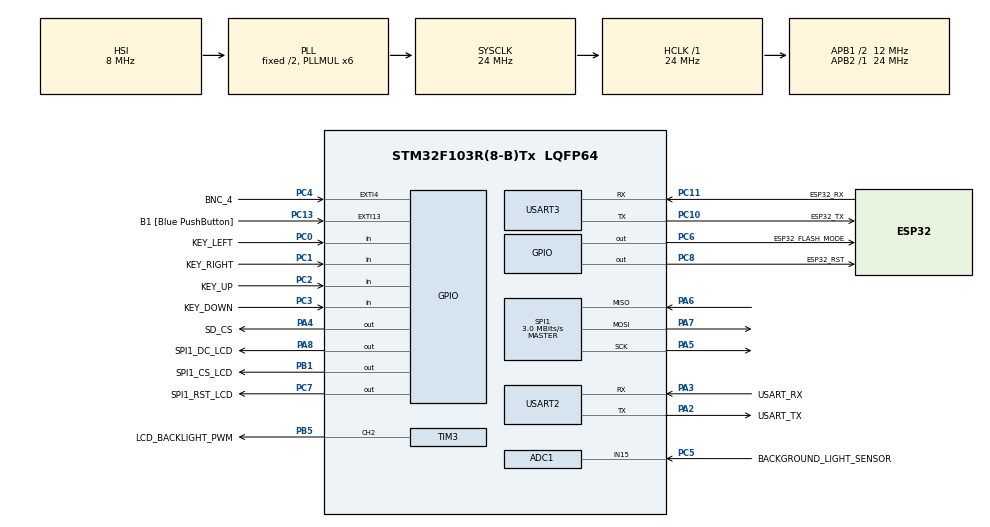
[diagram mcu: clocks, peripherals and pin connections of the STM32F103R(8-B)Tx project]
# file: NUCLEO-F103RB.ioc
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ADC1.Channel-3\#ChannelRegularConversion=ADC_CHANNEL_15
ADC1.ContinuousConvMode=ENABLE
ADC1.EnableRegularConversion=ENABLE
ADC1.NbrOfConversionFlag=1
ADC1.Rank-3\#ChannelRegularConversion=1
ADC1.SamplingTime-3\#ChannelRegularConversion=ADC_SAMPLETIME_1CYCLE_5
ADC1.master=1
Dma.ADC1.0.Direction=DMA_PERIPH_TO_MEMORY
Dma.ADC1.0.Instance=DMA1_Channel1
Dma.ADC1.0.MemDataAlignment=DMA_MDATAALIGN_WORD
Dma.ADC1.0.MemInc=DMA_MINC_ENABLE
Dma.ADC1.0.Mode=DMA_CIRCULAR
Dma.ADC1.0.PeriphDataAlignment=DMA_PDATAALIGN_WORD
Dma.ADC1.0.PeriphInc=DMA_PINC_DISABLE
Dma.ADC1.0.Priority=DMA_PRIORITY_MEDIUM
Dma.Request0=ADC1
Mcu.Family=STM32F1
Mcu.Name=STM32F103R(8-B)Tx
Mcu.Package=LQFP64
NVIC.DMA1_Channel1_IRQn=true\:0\:0\:false\:true\:true\:2\:false\:true\:true
NVIC.EXTI15_10_IRQn=true\:0\:0\:false\:true\:true\:3\:true\:true\:true
NVIC.EXTI4_IRQn=true\:0\:0\:false\:true\:true\:1\:true\:true\:true
NVIC.PriorityGroup=NVIC_PRIORITYGROUP_4
PA13.GPIO_Label=TMS
PA13.Mode=Serial_Wire
PA13.Signal=SYS_JTMS-SWDIO
PA14.GPIO_Label=TCK
PA14.Mode=Serial_Wire
PA14.Signal=SYS_JTCK-SWCLK
PA2.GPIO_Label=USART_TX
PA2.GPIO_Mode=GPIO_MODE_AF_PP
PA2.GPIO_PuPd=GPIO_NOPULL
PA2.GPIO_Speed=GPIO_SPEED_FREQ_LOW
PA2.Mode=Asynchronous
PA2.Signal=USART2_TX
PA3.GPIO_Label=USART_RX
PA3.GPIO_Mode=GPIO_MODE_AF_PP
PA3.GPIO_PuPd=GPIO_NOPULL
PA3.GPIO_Speed=GPIO_SPEED_FREQ_LOW
PA3.Mode=Asynchronous
PA3.Signal=USART2_RX
PA4.GPIO_Label=SD_CS
PA4.GPIO_PuPd=GPIO_PULLUP
PA4.Signal=GPIO_Output
PA5.Mode=Full_Duplex_Master
PA5.Signal=SPI1_SCK
PA6.GPIO_PuPd=GPIO_PULLUP
PA6.Mode=Full_Duplex_Master
PA6.Signal=SPI1_MISO
PA7.Mode=Full_Duplex_Master
PA7.Signal=SPI1_MOSI
PA8.GPIO_Label=SPI1_DC_LCD
PA8.GPIO_PuPd=GPIO_PULLUP
PA8.Signal=GPIO_Output
PB1.GPIO_Label=SPI1_CS_LCD
PB1.GPIO_PuPd=GPIO_PULLUP
PB1.Signal=GPIO_Output
PB3.GPIO_Label=SWO
PB3.Signal=SYS_JTDO-TRACESWO
PB5.GPIO_Label=LCD_BACKLIGHT_PWM
PB5.GPIO_Speed=GPIO_SPEED_FREQ_HIGH
PB5.Signal=S_TIM3_CH2
PC0.GPIO_Label=KEY_LEFT
PC0.GPIO_PuPd=GPIO_PULLUP
PC0.Signal=GPIO_Input
PC1.GPIO_Label=KEY_RIGHT
PC1.GPIO_PuPd=GPIO_PULLUP
PC1.Signal=GPIO_Input
PC10.GPIO_Label=ESP32_TX
PC10.Mode=Asynchronous
PC10.Signal=USART3_TX
PC11.GPIO_Label=ESP32_RX
PC11.Mode=Asynchronous
PC11.Signal=USART3_RX
PC12.Signal=USART3_CK
PC13-TAMPER-RTC.GPIO_Label=B1 [Blue PushButton]
PC13-TAMPER-RTC.GPIO_PuPd=GPIO_NOPULL
PC13-TAMPER-RTC.Signal=GPXTI13
PC14-OSC32_IN.Mode=LSE-External-Oscillator
PC14-OSC32_IN.Signal=RCC_OSC32_IN
PC15-OSC32_OUT.Mode=LSE-External-Oscillator
PC15-OSC32_OUT.Signal=RCC_OSC32_OUT
PC2.GPIO_Label=KEY_UP
PC2.GPIO_PuPd=GPIO_PULLUP
PC2.Signal=GPIO_Input
PC3.GPIO_Label=KEY_DOWN
PC3.GPIO_PuPd=GPIO_PULLUP
PC3.Signal=GPIO_Input
PC4.GPIO_Label=BNC_4
PC4.Signal=GPXTI4
PC5.GPIO_Label=BACKGROUND_LIGHT_SENSOR
PC5.Signal=ADCx_IN15
PC6.GPIO_Label=ESP32_FLASH_MODE
PC6.PinState=GPIO_PIN_SET
PC6.Signal=GPIO_Output
PC7.GPIO_Label=SPI1_RST_LCD
PC7.GPIO_PuPd=GPIO_PULLUP
PC7.PinState=GPIO_PIN_SET
PC7.Signal=GPIO_Output
PC8.GPIO_Label=ESP32_RST
PC8.PinState=GPIO_PIN_SET
PC8.Signal=GPIO_Output
PD0-OSC_IN.Mode=HSE-External-Oscillator
PD0-OSC_IN.Signal=RCC_OSC_IN
PD1-OSC_OUT.Mode=HSE-External-Oscillator
PD1-OSC_OUT.Signal=RCC_OSC_OUT
ProjectManager.HeapSize=0x200
ProjectManager.StackSize=0x400
ProjectManager.TargetToolchain=CMake
RCC.ADCPresc=RCC_ADCPCLK2_DIV8
RCC.AHBFreq_Value=24000000
RCC.APB1CLKDivider=RCC_HCLK_DIV2
RCC.APB1Freq_Value=12000000
RCC.APB1TimFreq_Value=24000000
RCC.APB2Freq_Value=24000000
RCC.APB2TimFreq_Value=24000000
RCC.HCLKFreq_Value=24000000
RCC.PLLMUL=RCC_PLL_MUL6
RCC.RTCClockSelection=RCC_RTCCLKSOURCE_LSE
RCC.SYSCLKFreq_VALUE=24000000
RCC.SYSCLKSource=RCC_SYSCLKSOURCE_PLLCLK
RCC.USBFreq_Value=24000000
SH.ADCx_IN15.0=ADC1_IN15,IN15
SH.S_TIM3_CH2.0=TIM3_CH2,PWM Generation2 CH2
SPI1.BaudRatePrescaler=SPI_BAUDRATEPRESCALER_8
SPI1.CalculateBaudRate=3.0 MBits/s
SPI1.Direction=SPI_DIRECTION_2LINES
SPI1.Mode=SPI_MODE_MASTER
SPI1.VirtualType=VM_MASTER
TIM3.Channel-PWM\ Generation2\ CH2=TIM_CHANNEL_2
TIM3.OCMode_PWM-PWM\ Generation2\ CH2=TIM_OCMODE_PWM2
TIM3.Period=100
TIM3.Prescaler=8
TIM3.Pulse-PWM\ Generation2\ CH2=30
USART2.VirtualMode=VM_ASYNC
USART3.VirtualMode=VM_ASYNC
VP_FATFS_VS_Generic.Mode=User_defined
VP_RTC_VS_RTC_Activate.Mode=RTC_Enabled
board=NUCLEO-F103RB

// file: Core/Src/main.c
/* USER CODE BEGIN Header */
/**
 ******************************************************************************
 * @file           : main.c
 * @brief          : Main program body
 ******************************************************************************
 * @attention
 *
 * Copyright (c) 2024 STMicroelectronics.
 * All rights reserved.
 *
 * This software is licensed under terms that can be found in the LICENSE file
 * in the root directory of this software component.
 * If no LICENSE file comes with this software, it is provided AS-IS.
 *
 ******************************************************************************
 */
/* USER CODE END Header */
#include "main.h"
#include "fatfs.h"

/* USER CODE BEGIN Includes */
#include "MyApplication.hpp"
/* USER CODE END Includes */

ADC_HandleTypeDef hadc1;
DMA_HandleTypeDef hdma_adc1;

RTC_HandleTypeDef hrtc;

SPI_HandleTypeDef hspi1;

TIM_HandleTypeDef htim3;

UART_HandleTypeDef huart2;
UART_HandleTypeDef huart3;

/* USER CODE BEGIN PV */

extern ADC_HandleTypeDef hadc1;
/*
// Declare a buffer to hold ADC values
#define ADC_BUFFER_SIZE 1  // Adjust size based on your needs
volatile uint32_t adcBuffer[ADC_BUFFER_SIZE];

void startADCWithDMA()
{
    // Start ADC in DMA mode
    HAL_StatusTypeDef statusFromHal = HAL_ADC_Start_DMA(&hadc1,  (uint32_t *)adcBuffer, ADC_BUFFER_SIZE);

    //return (statusFromHal == HAL_OK);
}
*/
/* USER CODE END PV */

void SystemClock_Config(void);
static void MX_GPIO_Init(void);
static void MX_DMA_Init(void);
static void MX_USART2_UART_Init(void);
static void MX_RTC_Init(void);
static void MX_SPI1_Init(void);
static void MX_ADC1_Init(void);
static void MX_USART3_UART_Init(void);
static void MX_TIM3_Init(void);
static void MX_NVIC_Init(void);

int main(void)
{

  /* MCU Configuration--------------------------------------------------------*/

  /* Reset of all peripherals, Initializes the Flash interface and the Systick. */
  HAL_Init();

  /* Configure the system clock */
  SystemClock_Config();

  /* Initialize all configured peripherals */
  MX_GPIO_Init();
  MX_DMA_Init();
  MX_USART2_UART_Init();
  MX_FATFS_Init();
  MX_RTC_Init();
  MX_SPI1_Init();
  MX_ADC1_Init();
  MX_USART3_UART_Init();
  MX_TIM3_Init();

  /* Initialize interrupts */
  MX_NVIC_Init();
  /* USER CODE BEGIN 2 */
  // startADCWithDMA();
  app_init();
  app_start(); // maybe do a bit of sleep before calling it
  /* USER CODE END 2 */

  /* Infinite loop */
  while (1)
  {

    /* USER CODE BEGIN 3 */
    app_tick();
  }
  /* USER CODE END 3 */
}

void SystemClock_Config(void)
{
  RCC_OscInitTypeDef RCC_OscInitStruct = {0};
  RCC_ClkInitTypeDef RCC_ClkInitStruct = {0};
  RCC_PeriphCLKInitTypeDef PeriphClkInit = {0};

  /** Initializes the RCC Oscillators according to the specified parameters
  * in the RCC_OscInitTypeDef structure.
  */
  RCC_OscInitStruct.OscillatorType = RCC_OSCILLATORTYPE_HSI|RCC_OSCILLATORTYPE_LSE;
  RCC_OscInitStruct.LSEState = RCC_LSE_ON;
  RCC_OscInitStruct.HSIState = RCC_HSI_ON;
  RCC_OscInitStruct.HSICalibrationValue = RCC_HSICALIBRATION_DEFAULT;
  RCC_OscInitStruct.PLL.PLLState = RCC_PLL_ON;
  RCC_OscInitStruct.PLL.PLLSource = RCC_PLLSOURCE_HSI_DIV2;
  RCC_OscInitStruct.PLL.PLLMUL = RCC_PLL_MUL6;
  if (HAL_RCC_OscConfig(&RCC_OscInitStruct) != HAL_OK)
  {
    Error_Handler();
  }

  /** Initializes the CPU, AHB and APB buses clocks
  */
  RCC_ClkInitStruct.ClockType = RCC_CLOCKTYPE_HCLK|RCC_CLOCKTYPE_SYSCLK
                              |RCC_CLOCKTYPE_PCLK1|RCC_CLOCKTYPE_PCLK2;
  RCC_ClkInitStruct.SYSCLKSource = RCC_SYSCLKSOURCE_PLLCLK;
  RCC_ClkInitStruct.AHBCLKDivider = RCC_SYSCLK_DIV1;
  RCC_ClkInitStruct.APB1CLKDivider = RCC_HCLK_DIV2;
  RCC_ClkInitStruct.APB2CLKDivider = RCC_HCLK_DIV1;

  if (HAL_RCC_ClockConfig(&RCC_ClkInitStruct, FLASH_LATENCY_0) != HAL_OK)
  {
    Error_Handler();
  }
  PeriphClkInit.PeriphClockSelection = RCC_PERIPHCLK_RTC|RCC_PERIPHCLK_ADC;
  PeriphClkInit.RTCClockSelection = RCC_RTCCLKSOURCE_LSE;
  PeriphClkInit.AdcClockSelection = RCC_ADCPCLK2_DIV8;
  if (HAL_RCCEx_PeriphCLKConfig(&PeriphClkInit) != HAL_OK)
  {
    Error_Handler();
  }
}

/**
  * @brief NVIC Configuration.
  * @retval None
  */
static void MX_NVIC_Init(void)
{
  /* EXTI4_IRQn interrupt configuration */
  HAL_NVIC_SetPriority(EXTI4_IRQn, 0, 0);
  HAL_NVIC_EnableIRQ(EXTI4_IRQn);
  /* DMA1_Channel1_IRQn interrupt configuration */
  HAL_NVIC_SetPriority(DMA1_Channel1_IRQn, 0, 0);
  HAL_NVIC_EnableIRQ(DMA1_Channel1_IRQn);
  /* EXTI15_10_IRQn interrupt configuration */
  HAL_NVIC_SetPriority(EXTI15_10_IRQn, 0, 0);
  HAL_NVIC_EnableIRQ(EXTI15_10_IRQn);
}

static void MX_ADC1_Init(void)
{

  ADC_ChannelConfTypeDef sConfig = {0};

  /** Common config
  */
  hadc1.Instance = ADC1;
  hadc1.Init.ScanConvMode = ADC_SCAN_DISABLE;
  hadc1.Init.ContinuousConvMode = ENABLE;
  hadc1.Init.DiscontinuousConvMode = DISABLE;
  hadc1.Init.ExternalTrigConv = ADC_SOFTWARE_START;
  hadc1.Init.DataAlign = ADC_DATAALIGN_RIGHT;
  hadc1.Init.NbrOfConversion = 1;
  if (HAL_ADC_Init(&hadc1) != HAL_OK)
  {
    Error_Handler();
  }

  /** Configure Regular Channel
  */
  sConfig.Channel = ADC_CHANNEL_15;
  sConfig.Rank = ADC_REGULAR_RANK_1;
  sConfig.SamplingTime = ADC_SAMPLETIME_1CYCLE_5;
  if (HAL_ADC_ConfigChannel(&hadc1, &sConfig) != HAL_OK)
  {
    Error_Handler();
  }

}

static void MX_RTC_Init(void)
{

  /** Initialize RTC Only
  */
  hrtc.Instance = RTC;
  hrtc.Init.AsynchPrediv = RTC_AUTO_1_SECOND;
  hrtc.Init.OutPut = RTC_OUTPUTSOURCE_ALARM;
  if (HAL_RTC_Init(&hrtc) != HAL_OK)
  {
    Error_Handler();
  }

}

static void MX_SPI1_Init(void)
{

  /* SPI1 parameter configuration*/
  hspi1.Instance = SPI1;
  hspi1.Init.Mode = SPI_MODE_MASTER;
  hspi1.Init.Direction = SPI_DIRECTION_2LINES;
  hspi1.Init.DataSize = SPI_DATASIZE_8BIT;
  hspi1.Init.CLKPolarity = SPI_POLARITY_LOW;
  hspi1.Init.CLKPhase = SPI_PHASE_1EDGE;
  hspi1.Init.NSS = SPI_NSS_SOFT;
  hspi1.Init.BaudRatePrescaler = SPI_BAUDRATEPRESCALER_8;
  hspi1.Init.FirstBit = SPI_FIRSTBIT_MSB;
  hspi1.Init.TIMode = SPI_TIMODE_DISABLE;
  hspi1.Init.CRCCalculation = SPI_CRCCALCULATION_DISABLE;
  hspi1.Init.CRCPolynomial = 10;
  if (HAL_SPI_Init(&hspi1) != HAL_OK)
  {
    Error_Handler();
  }

}

static void MX_TIM3_Init(void)
{

  TIM_MasterConfigTypeDef sMasterConfig = {0};
  TIM_OC_InitTypeDef sConfigOC = {0};

  htim3.Instance = TIM3;
  htim3.Init.Prescaler = 8;
  htim3.Init.CounterMode = TIM_COUNTERMODE_UP;
  htim3.Init.Period = 100;
  htim3.Init.ClockDivision = TIM_CLOCKDIVISION_DIV1;
  htim3.Init.AutoReloadPreload = TIM_AUTORELOAD_PRELOAD_DISABLE;
  if (HAL_TIM_PWM_Init(&htim3) != HAL_OK)
  {
    Error_Handler();
  }
  sMasterConfig.MasterOutputTrigger = TIM_TRGO_RESET;
  sMasterConfig.MasterSlaveMode = TIM_MASTERSLAVEMODE_DISABLE;
  if (HAL_TIMEx_MasterConfigSynchronization(&htim3, &sMasterConfig) != HAL_OK)
  {
    Error_Handler();
  }
  sConfigOC.OCMode = TIM_OCMODE_PWM2;
  sConfigOC.Pulse = 30;
  sConfigOC.OCPolarity = TIM_OCPOLARITY_HIGH;
  sConfigOC.OCFastMode = TIM_OCFAST_DISABLE;
  if (HAL_TIM_PWM_ConfigChannel(&htim3, &sConfigOC, TIM_CHANNEL_2) != HAL_OK)
  {
    Error_Handler();
  }
  HAL_TIM_MspPostInit(&htim3);

}

static void MX_USART2_UART_Init(void)
{

  huart2.Instance = USART2;
  huart2.Init.BaudRate = 115200;
  huart2.Init.WordLength = UART_WORDLENGTH_8B;
  huart2.Init.StopBits = UART_STOPBITS_1;
  huart2.Init.Parity = UART_PARITY_NONE;
  huart2.Init.Mode = UART_MODE_TX_RX;
  huart2.Init.HwFlowCtl = UART_HWCONTROL_NONE;
  huart2.Init.OverSampling = UART_OVERSAMPLING_16;
  if (HAL_UART_Init(&huart2) != HAL_OK)
  {
    Error_Handler();
  }

}

static void MX_USART3_UART_Init(void)
{

  huart3.Instance = USART3;
  huart3.Init.BaudRate = 115200;
  huart3.Init.WordLength = UART_WORDLENGTH_8B;
  huart3.Init.StopBits = UART_STOPBITS_1;
  huart3.Init.Parity = UART_PARITY_NONE;
  huart3.Init.Mode = UART_MODE_TX_RX;
  huart3.Init.HwFlowCtl = UART_HWCONTROL_NONE;
  huart3.Init.OverSampling = UART_OVERSAMPLING_16;
  if (HAL_UART_Init(&huart3) != HAL_OK)
  {
    Error_Handler();
  }

}

static void MX_DMA_Init(void)
{

  /* DMA controller clock enable */
  __HAL_RCC_DMA1_CLK_ENABLE();

}

static void MX_GPIO_Init(void)
{
  GPIO_InitTypeDef GPIO_InitStruct = {0};

  /* GPIO Ports Clock Enable */
  __HAL_RCC_GPIOC_CLK_ENABLE();
  __HAL_RCC_GPIOD_CLK_ENABLE();
  __HAL_RCC_GPIOA_CLK_ENABLE();
  __HAL_RCC_GPIOB_CLK_ENABLE();

  /*Configure GPIO pin Output Level */
  HAL_GPIO_WritePin(GPIOA, SD_CS_Pin|SPI1_DC_LCD_Pin, GPIO_PIN_RESET);

  /*Configure GPIO pin Output Level */
  HAL_GPIO_WritePin(SPI1_CS_LCD_GPIO_Port, SPI1_CS_LCD_Pin, GPIO_PIN_RESET);

  /*Configure GPIO pin Output Level */
  HAL_GPIO_WritePin(GPIOC, ESP32_FLASH_MODE_Pin|SPI1_RST_LCD_Pin|ESP32_RST_Pin, GPIO_PIN_SET);

  /*Configure GPIO pins : B1_Pin BNC_4_Pin */
  GPIO_InitStruct.Pin = B1_Pin|BNC_4_Pin;
  GPIO_InitStruct.Mode = GPIO_MODE_IT_RISING;
  GPIO_InitStruct.Pull = GPIO_NOPULL;
  HAL_GPIO_Init(GPIOC, &GPIO_InitStruct);

  /*Configure GPIO pins : KEY_LEFT_Pin KEY_RIGHT_Pin KEY_UP_Pin KEY_DOWN_Pin */
  GPIO_InitStruct.Pin = KEY_LEFT_Pin|KEY_RIGHT_Pin|KEY_UP_Pin|KEY_DOWN_Pin;
  GPIO_InitStruct.Mode = GPIO_MODE_INPUT;
  GPIO_InitStruct.Pull = GPIO_PULLUP;
  HAL_GPIO_Init(GPIOC, &GPIO_InitStruct);

  /*Configure GPIO pins : SD_CS_Pin SPI1_DC_LCD_Pin */
  GPIO_InitStruct.Pin = SD_CS_Pin|SPI1_DC_LCD_Pin;
  GPIO_InitStruct.Mode = GPIO_MODE_OUTPUT_PP;
  GPIO_InitStruct.Pull = GPIO_PULLUP;
  GPIO_InitStruct.Speed = GPIO_SPEED_FREQ_LOW;
  HAL_GPIO_Init(GPIOA, &GPIO_InitStruct);

  /*Configure GPIO pin : SPI1_CS_LCD_Pin */
  GPIO_InitStruct.Pin = SPI1_CS_LCD_Pin;
  GPIO_InitStruct.Mode = GPIO_MODE_OUTPUT_PP;
  GPIO_InitStruct.Pull = GPIO_PULLUP;
  GPIO_InitStruct.Speed = GPIO_SPEED_FREQ_LOW;
  HAL_GPIO_Init(SPI1_CS_LCD_GPIO_Port, &GPIO_InitStruct);

  /*Configure GPIO pins : ESP32_FLASH_MODE_Pin ESP32_RST_Pin */
  GPIO_InitStruct.Pin = ESP32_FLASH_MODE_Pin|ESP32_RST_Pin;
  GPIO_InitStruct.Mode = GPIO_MODE_OUTPUT_PP;
  GPIO_InitStruct.Pull = GPIO_NOPULL;
  GPIO_InitStruct.Speed = GPIO_SPEED_FREQ_LOW;
  HAL_GPIO_Init(GPIOC, &GPIO_InitStruct);

  /*Configure GPIO pin : SPI1_RST_LCD_Pin */
  GPIO_InitStruct.Pin = SPI1_RST_LCD_Pin;
  GPIO_InitStruct.Mode = GPIO_MODE_OUTPUT_PP;
  GPIO_InitStruct.Pull = GPIO_PULLUP;
  GPIO_InitStruct.Speed = GPIO_SPEED_FREQ_LOW;
  HAL_GPIO_Init(SPI1_RST_LCD_GPIO_Port, &GPIO_InitStruct);

}

void Error_Handler(void)
{
  __disable_irq();
  while (1)
  {
  }
}
